VERSION ""

NS_ :

BS_:

BU_: PowerStage Master

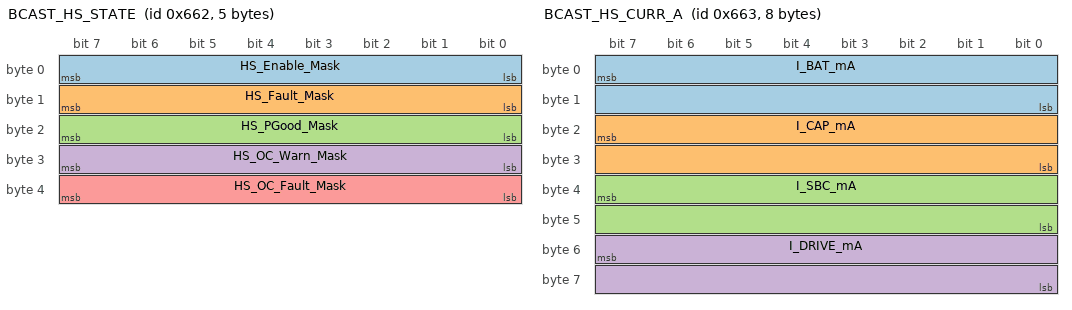
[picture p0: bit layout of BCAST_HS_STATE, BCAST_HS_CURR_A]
BO_ 1634 BCAST_HS_STATE : 5 PowerStage
 SG_ HS_Enable_Mask    : 0|8@1+  (1,0)       [0|31]   ""      Master
 SG_ HS_Fault_Mask     : 8|8@1+  (1,0)       [0|31]   ""      Master
 SG_ HS_PGood_Mask     : 16|8@1+ (1,0)       [0|31]   ""      Master
 SG_ HS_OC_Warn_Mask   : 24|8@1+ (1,0)       [0|31]   ""      Master
 SG_ HS_OC_Fault_Mask  : 32|8@1+ (1,0)       [0|31]   ""      Master

BO_ 1635 BCAST_HS_CURR_A : 8 PowerStage
 SG_ I_BAT_mA          : 7|16@0+  (0.001,0)  [0|50]   "A"     Master
 SG_ I_CAP_mA          : 23|16@0+ (0.001,0)  [0|50]   "A"     Master
 SG_ I_SBC_mA          : 39|16@0+ (0.001,0)  [0|50]   "A"     Master
 SG_ I_DRIVE_mA        : 55|16@0+ (0.001,0)  [0|50]   "A"     Master

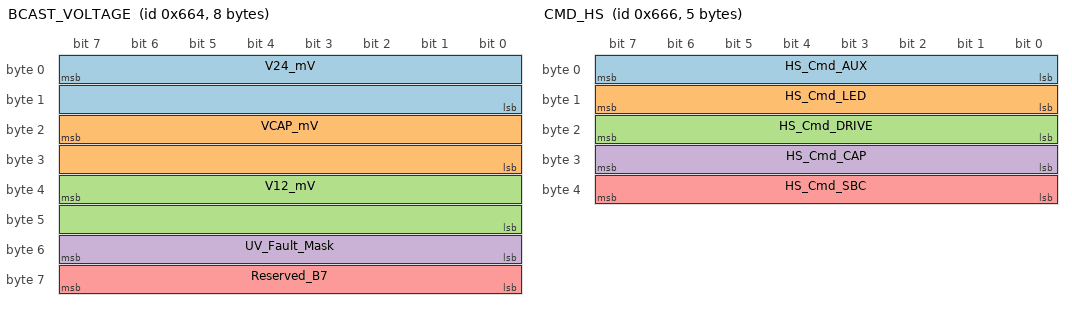
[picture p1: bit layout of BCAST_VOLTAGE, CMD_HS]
BO_ 1636 BCAST_VOLTAGE : 8 PowerStage
 SG_ V24_mV            : 7|16@0+  (0.001,0)  [0|30]   "V"     Master
 SG_ VCAP_mV           : 23|16@0+ (0.001,0)  [0|30]   "V"     Master
 SG_ V12_mV            : 39|16@0+ (0.001,0)  [0|15]   "V"     Master
 SG_ UV_Fault_Mask     : 48|8@1+  (1,0)      [0|7]    ""      Master
 SG_ Reserved_B7       : 56|8@1+  (1,0)      [0|255]  ""      Master

BO_ 1637 CMD_FAN : 2 Master
 SG_ Fan_Mode          : 0|8@1+  (1,0)       [0|2]    ""      PowerStage
 SG_ Fan_Duty          : 8|8@1+  (1,0)       [0|100]  "%"     PowerStage

BO_ 1638 CMD_HS : 5 Master
 SG_ HS_Cmd_AUX        : 0|8@1+  (1,0)       [0|1]    ""      PowerStage
 SG_ HS_Cmd_LED        : 8|8@1+  (1,0)       [0|1]    ""      PowerStage
 SG_ HS_Cmd_DRIVE      : 16|8@1+ (1,0)       [0|1]    ""      PowerStage
 SG_ HS_Cmd_CAP        : 24|8@1+ (1,0)       [0|1]    ""      PowerStage
 SG_ HS_Cmd_SBC        : 32|8@1+ (1,0)       [0|1]    ""      PowerStage

BO_ 1639 DEVICE_ADDR : 2 Master
 SG_ Device_Command    : 0|8@1+  (1,0)       [0|255]  ""      PowerStage

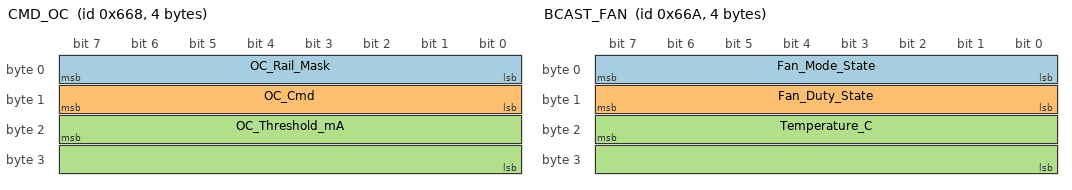
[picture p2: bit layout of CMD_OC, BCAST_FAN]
BO_ 1640 CMD_OC : 4 Master
 SG_ OC_Rail_Mask      : 0|8@1+  (1,0)       [0|255]  ""      PowerStage
 SG_ OC_Cmd            : 8|8@1+  (1,0)       [0|255]  ""      PowerStage
 SG_ OC_Threshold_mA   : 23|16@0+(0.001,0)   [0|50]   "A"     PowerStage

BO_ 1641 CMD_EEPROM : 1 Master
 SG_ EEPROM_Cmd        : 0|8@1+  (1,0)       [0|255]  ""      PowerStage

BO_ 1642 BCAST_FAN : 4 PowerStage
 SG_ Fan_Mode_State    : 0|8@1+  (1,0)       [0|2]    ""      Master
 SG_ Fan_Duty_State    : 8|8@1+  (1,0)       [0|100]  "%"     Master
 SG_ Temperature_C     : 23|16@0-(0.1,0)     [-40|150] "degC" Master

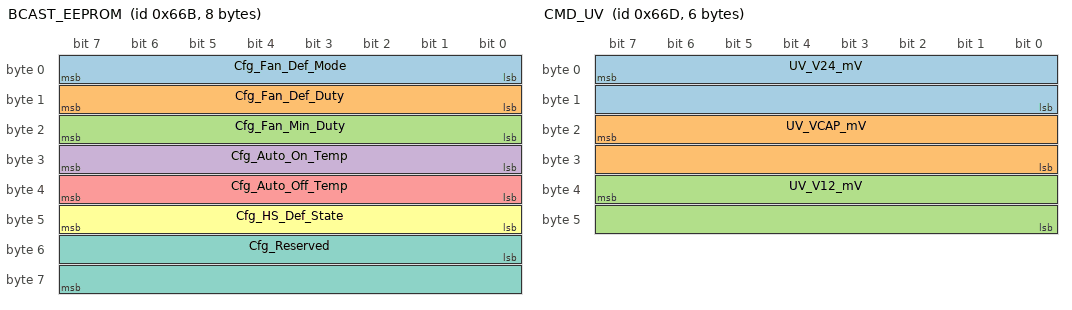
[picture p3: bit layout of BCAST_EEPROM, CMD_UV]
BO_ 1643 BCAST_EEPROM : 8 PowerStage
 SG_ Cfg_Fan_Def_Mode  : 0|8@1+  (1,0)       [0|2]    ""      Master
 SG_ Cfg_Fan_Def_Duty  : 8|8@1+  (1,0)       [0|100]  "%"     Master
 SG_ Cfg_Fan_Min_Duty  : 16|8@1+ (1,0)       [0|100]  "%"     Master
 SG_ Cfg_Auto_On_Temp  : 24|8@1+ (1,0)       [0|150]  "degC"  Master
 SG_ Cfg_Auto_Off_Temp : 32|8@1+ (1,0)       [0|150]  "degC"  Master
 SG_ Cfg_HS_Def_State  : 40|8@1+ (1,0)       [0|31]   ""      Master
 SG_ Cfg_Reserved      : 48|16@1+(1,0)       [0|65535] ""     Master

BO_ 1644 BCAST_HS_CURR_B : 4 PowerStage
 SG_ I_AUX_mA          : 7|16@0+  (0.001,0)  [0|50]   "A"     Master
 SG_ I_LED_mA          : 23|16@0+ (0.001,0)  [0|50]   "A"     Master

BO_ 1645 CMD_UV : 6 Master
 SG_ UV_V24_mV         : 7|16@0+  (0.001,0)  [0|30]   "V"     PowerStage
 SG_ UV_VCAP_mV        : 23|16@0+ (0.001,0)  [0|30]   "V"     PowerStage
 SG_ UV_V12_mV         : 39|16@0+ (0.001,0)  [0|15]   "V"     PowerStage

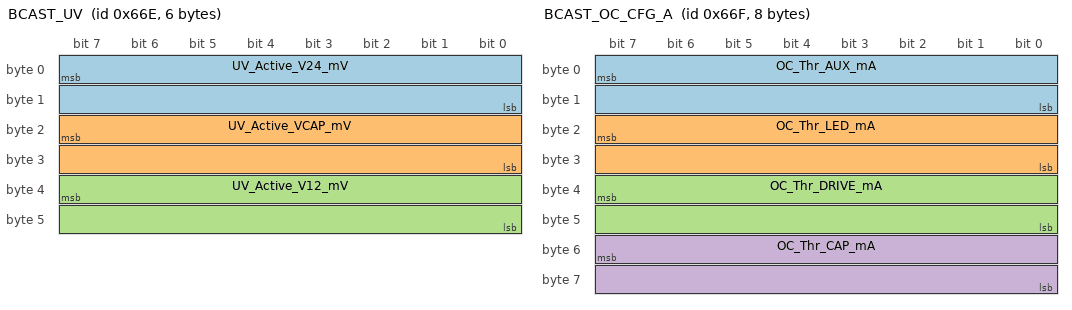
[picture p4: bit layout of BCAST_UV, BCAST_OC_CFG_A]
BO_ 1646 BCAST_UV : 6 PowerStage
 SG_ UV_Active_V24_mV  : 7|16@0+  (0.001,0)  [0|30]   "V"     Master
 SG_ UV_Active_VCAP_mV : 23|16@0+ (0.001,0)  [0|30]   "V"     Master
 SG_ UV_Active_V12_mV  : 39|16@0+ (0.001,0)  [0|15]   "V"     Master

BO_ 1647 BCAST_OC_CFG_A : 8 PowerStage
 SG_ OC_Thr_AUX_mA    : 7|16@0+  (0.001,0)  [0|50]   "A"     Master
 SG_ OC_Thr_LED_mA    : 23|16@0+ (0.001,0)  [0|50]   "A"     Master
 SG_ OC_Thr_DRIVE_mA  : 39|16@0+ (0.001,0)  [0|50]   "A"     Master
 SG_ OC_Thr_CAP_mA    : 55|16@0+ (0.001,0)  [0|50]   "A"     Master

BO_ 1648 BCAST_OC_CFG_B : 2 PowerStage
 SG_ OC_Thr_SBC_mA    : 7|16@0+  (0.001,0)  [0|50]   "A"     Master

BO_ 1649 CMD_CTRL : 2 Master
 SG_ V_LED_PWR_Cmd     : 0|8@1+  (1,0)       [0|1]    ""      PowerStage
 SG_ CAN_Relay_Enable  : 8|8@1+  (1,0)       [0|1]    ""      PowerStage

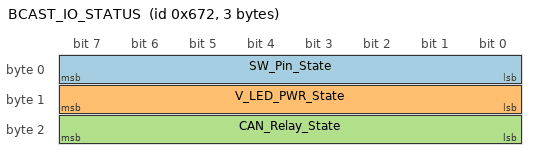
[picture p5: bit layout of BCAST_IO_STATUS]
BO_ 1650 BCAST_IO_STATUS : 3 PowerStage
 SG_ SW_Pin_State      : 0|8@1+  (1,0)       [0|1]    ""      Master
 SG_ V_LED_PWR_State   : 8|8@1+  (1,0)       [0|1]    ""      Master
 SG_ CAN_Relay_State   : 16|8@1+ (1,0)       [0|1]    ""      Master

CM_ BU_ PowerStage "STM32G0B1 PowerStage controller. Manages 5 TPS2493 hot-swap rails, fan, ADC and EEPROM config. Dual CAN bus: FDCAN1 (PB8/PB9) = internal, FDCAN2 (PC2/PC3) = host relay. All messages mirrored on both buses.";
CM_ BU_ Master "Supervisory host or gateway node that issues commands to PowerStage. Can connect to either CAN1 or CAN2 bus.";

CM_ BO_ 1634 "Periodic HS rail status. Bitmask bit order: bit0=AUX bit1=LED bit2=DRIVE bit3=CAP bit4=SBC. Sent on both CAN1+CAN2.";
CM_ BO_ 1635 "Periodic broadcast of BAT, CAP, SBC, DRIVE rail currents. uint16 mA big-endian, scale 0.001 for A.";
CM_ BO_ 1636 "Periodic broadcast of V24, VCAP, V12 voltages in mV and UV fault bitmask. Scale 0.001 for V.";
CM_ BO_ 1637 "Command: set fan mode and manual duty cycle. Accepted from both CAN buses.";
CM_ BO_ 1638 "Command: individually enable or disable each of the 5 HS rails. Accepted from both CAN buses.";
CM_ BO_ 1639 "Command: system-level control. 0xFF triggers reset and re-enters OpenBLT bootloader. Accepted from both CAN buses.";
CM_ BO_ 1640 "Command: configure per-rail software OC threshold or clear latched OC faults. OC_Rail_Mask 0xFF = all rails.";
CM_ BO_ 1641 "Command: EEPROM operations. 0x01 saves live config; 0x02 restores factory defaults.";
CM_ BO_ 1642 "Periodic broadcast of fan mode, duty cycle and NTC temperature. Temp is int16 degCx10, scale 0.1 for degC.";
CM_ BO_ 1643 "Periodic echo of EEPROM-stored configuration defaults.";
CM_ BO_ 1644 "Periodic broadcast of AUX and LED rail currents. uint16 mA big-endian, scale 0.001 for A.";
CM_ BO_ 1645 "Command: update UV trip thresholds for V24, VCAP, V12 in mV big-endian.";
CM_ BO_ 1646 "Periodic broadcast of currently active UV thresholds.";
CM_ BO_ 1647 "Periodic broadcast of OC thresholds for AUX, LED, DRIVE, CAP rails (frame A of 2).";
CM_ BO_ 1648 "Periodic broadcast of OC threshold for SBC rail (frame B of 2).";
CM_ BO_ 1649 "Command: control V_LED_PWR output and CAN relay enable/disable. Accepted from both CAN buses.";
CM_ BO_ 1650 "Periodic broadcast of SW pin state, V_LED_PWR output state, and CAN relay enabled status.";

CM_ SG_ 1634 HS_Enable_Mask   "1=rail EN GPIO asserted. bit0=AUX bit1=LED bit2=DRIVE bit3=CAP bit4=SBC.";
CM_ SG_ 1634 HS_Fault_Mask    "1=TPS2493 hardware FLT pin asserted (latched fault).";
CM_ SG_ 1634 HS_PGood_Mask    "1=TPS2493 PGOOD pin asserted (rail healthy).";
CM_ SG_ 1634 HS_OC_Warn_Mask  "1=software OC warning threshold exceeded for this rail.";
CM_ SG_ 1634 HS_OC_Fault_Mask "1=hardware OC fault latched (TPS2493 FLT triggered by OC).";
CM_ SG_ 1635 I_BAT_mA         "Battery input current. uint16 mA big-endian. Scale 0.001 for A.";
CM_ SG_ 1635 I_CAP_mA         "Capacitor rail current. uint16 mA big-endian.";
CM_ SG_ 1635 I_SBC_mA         "SBC rail current. uint16 mA big-endian.";
CM_ SG_ 1635 I_DRIVE_mA       "Drive rail current. uint16 mA big-endian.";
CM_ SG_ 1636 V24_mV           "24V bus voltage in mV big-endian. Scale 0.001 for V.";
CM_ SG_ 1636 VCAP_mV          "Capacitor bus voltage in mV big-endian.";
CM_ SG_ 1636 V12_mV           "12V bus voltage in mV big-endian.";
CM_ SG_ 1636 UV_Fault_Mask    "UV fault bitmask. bit0=V24 UV, bit1=VCAP UV, bit2=V12 UV.";
CM_ SG_ 1637 Fan_Mode         "0=OFF 1=ON_MANUAL 2=AUTO. In AUTO mode Fan_Duty is ignored.";
CM_ SG_ 1637 Fan_Duty         "Manual duty cycle 0-100%. Applied only when Fan_Mode=1.";
CM_ SG_ 1638 HS_Cmd_AUX       "0=disable RAIL_AUX 1=enable.";
CM_ SG_ 1638 HS_Cmd_LED       "0=disable RAIL_LED 1=enable.";
CM_ SG_ 1638 HS_Cmd_DRIVE     "0=disable RAIL_DRIVE 1=enable.";
CM_ SG_ 1638 HS_Cmd_CAP       "0=disable RAIL_CAP 1=enable.";
CM_ SG_ 1638 HS_Cmd_SBC       "0=disable RAIL_SBC 1=enable. Note: SBC has no EN GPIO, field reserved.";
CM_ SG_ 1639 Device_Command   "0xFF = software reset and re-enter OpenBLT bootloader.";
CM_ SG_ 1640 OC_Rail_Mask     "Target rail bitmask. 0xFF applies command to all rails.";
CM_ SG_ 1640 OC_Cmd           "0x01=SET_THRESHOLD (apply OC_Threshold_mA). 0x02=RESET_FAULT (clear masks).";
CM_ SG_ 1640 OC_Threshold_mA  "New software OC warning threshold in mA big-endian. Applied to rails in OC_Rail_Mask when Cmd=0x01.";
CM_ SG_ 1641 EEPROM_Cmd       "0x01=save live config to EEPROM. 0x02=load factory defaults and overwrite EEPROM.";
CM_ SG_ 1642 Fan_Mode_State   "Current active fan mode.";
CM_ SG_ 1642 Fan_Duty_State   "Current active PWM duty cycle 0-100%.";
CM_ SG_ 1642 Temperature_C    "NTC temperature. int16 degCx10 big-endian. Scale 0.1 for degC. e.g. 253 = 25.3 degC.";
CM_ SG_ 1643 Cfg_Fan_Def_Mode "EEPROM default fan mode applied at boot.";
CM_ SG_ 1643 Cfg_Fan_Def_Duty "EEPROM default fan duty cycle applied at boot.";
CM_ SG_ 1643 Cfg_Fan_Min_Duty "Minimum PWM duty before stall prevention kicks in.";
CM_ SG_ 1643 Cfg_Auto_On_Temp "AUTO mode: fan turns ON above this temperature (degC).";
CM_ SG_ 1643 Cfg_Auto_Off_Temp "AUTO mode: fan turns OFF below this temperature (degC, hysteresis).";
CM_ SG_ 1643 Cfg_HS_Def_State "HS rail bitmask applied at boot. bit0=AUX bit1=LED bit2=DRIVE bit3=CAP bit4=SBC.";
CM_ SG_ 1644 I_AUX_mA        "AUX rail current. uint16 mA big-endian. Scale 0.001 for A.";
CM_ SG_ 1644 I_LED_mA        "LED rail current. uint16 mA big-endian.";
CM_ SG_ 1645 UV_V24_mV       "New UV trip threshold for V24 bus in mV big-endian.";
CM_ SG_ 1645 UV_VCAP_mV      "New UV trip threshold for VCAP bus in mV big-endian.";
CM_ SG_ 1645 UV_V12_mV       "New UV trip threshold for V12 bus in mV big-endian.";
CM_ SG_ 1646 UV_Active_V24_mV  "Active UV threshold for V24 bus in mV.";
CM_ SG_ 1646 UV_Active_VCAP_mV "Active UV threshold for VCAP bus in mV.";
CM_ SG_ 1646 UV_Active_V12_mV  "Active UV threshold for V12 bus in mV.";
CM_ SG_ 1647 OC_Thr_AUX_mA    "Software OC threshold for AUX rail in mA.";
CM_ SG_ 1647 OC_Thr_LED_mA    "Software OC threshold for LED rail in mA.";
CM_ SG_ 1647 OC_Thr_DRIVE_mA  "Software OC threshold for DRIVE rail in mA.";
CM_ SG_ 1647 OC_Thr_CAP_mA    "Software OC threshold for CAP rail in mA.";
CM_ SG_ 1648 OC_Thr_SBC_mA    "Software OC threshold for SBC rail in mA.";
CM_ SG_ 1649 V_LED_PWR_Cmd    "0=OFF 1=ON. Controls V_LED_PWR output (PC0).";
CM_ SG_ 1649 CAN_Relay_Enable "0=disable relay 1=enable relay. Controls CAN1<->CAN2 frame forwarding.";
CM_ SG_ 1650 SW_Pin_State     "Current state of SW pin (PC1). 0=LOW 1=HIGH.";
CM_ SG_ 1650 V_LED_PWR_State  "Current output state of V_LED_PWR (PC0). 0=OFF 1=ON.";
CM_ SG_ 1650 CAN_Relay_State  "Current state of CAN relay. 0=disabled 1=enabled.";

BA_DEF_ BO_ "GenMsgCycleTime" INT 0 10000;
BA_DEF_ BO_ "GenMsgSendType"  STRING;
BA_DEF_ SG_ "GenSigSendType"  STRING;

BA_DEF_DEF_ "GenMsgCycleTime" 0;
BA_DEF_DEF_ "GenMsgSendType"  "Cyclic";
BA_DEF_DEF_ "GenSigSendType"  "Cyclic";

BA_ "GenMsgCycleTime" BO_ 1634 500;
BA_ "GenMsgCycleTime" BO_ 1635 500;
BA_ "GenMsgCycleTime" BO_ 1636 500;
BA_ "GenMsgCycleTime" BO_ 1642 500;
BA_ "GenMsgCycleTime" BO_ 1643 500;
BA_ "GenMsgCycleTime" BO_ 1644 500;
BA_ "GenMsgCycleTime" BO_ 1646 500;
BA_ "GenMsgCycleTime" BO_ 1647 500;
BA_ "GenMsgCycleTime" BO_ 1648 500;
BA_ "GenMsgCycleTime" BO_ 1650 500;
BA_ "GenMsgSendType"  BO_ 1637 "Event";
BA_ "GenMsgSendType"  BO_ 1638 "Event";
BA_ "GenMsgSendType"  BO_ 1639 "Event";
BA_ "GenMsgSendType"  BO_ 1640 "Event";
BA_ "GenMsgSendType"  BO_ 1641 "Event";
BA_ "GenMsgSendType"  BO_ 1645 "Event";
BA_ "GenMsgSendType"  BO_ 1649 "Event";

VAL_ 1637 Fan_Mode        0 "OFF" 1 "ON_MANUAL" 2 "AUTO" ;
VAL_ 1638 HS_Cmd_AUX      0 "DISABLE" 1 "ENABLE" ;
VAL_ 1638 HS_Cmd_LED      0 "DISABLE" 1 "ENABLE" ;
VAL_ 1638 HS_Cmd_DRIVE    0 "DISABLE" 1 "ENABLE" ;
VAL_ 1638 HS_Cmd_CAP      0 "DISABLE" 1 "ENABLE" ;
VAL_ 1638 HS_Cmd_SBC      0 "DISABLE" 1 "ENABLE" ;
VAL_ 1639 Device_Command  255 "RESET_BOOTLOADER" ;
VAL_ 1640 OC_Cmd          1 "SET_THRESHOLD" 2 "RESET_FAULT" ;
VAL_ 1641 EEPROM_Cmd      1 "SAVE_CONFIG" 2 "LOAD_DEFAULT" ;
VAL_ 1642 Fan_Mode_State  0 "OFF" 1 "ON_MANUAL" 2 "AUTO" ;
VAL_ 1643 Cfg_Fan_Def_Mode 0 "OFF" 1 "ON_MANUAL" 2 "AUTO" ;
VAL_ 1649 V_LED_PWR_Cmd    0 "OFF" 1 "ON" ;
VAL_ 1649 CAN_Relay_Enable 0 "DISABLE" 1 "ENABLE" ;
